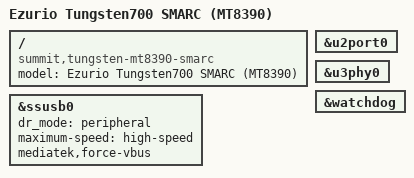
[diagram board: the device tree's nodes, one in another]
// SPDX-License-Identifier: (GPL-2.0 OR MIT)
/*
 * Copyright (C) 2026 Ezurio LLC
 */

/dts-v1/;

#include "tungsten-mt8390-smarc.dtsi"

/ {
	model = "Ezurio Tungsten700 SMARC (MT8390)";
	compatible = "summit,tungsten-mt8390-smarc",
	             "mediatek,mt8390", "mediatek,mt8188";
};

&ssusb0 {
	dr_mode = "peripheral";
	maximum-speed = "high-speed";
	/* VBUS-valid is not sensed by the SoC in device role; BROM forces it, so do the same */
	mediatek,force-vbus;

	status = "okay";
};

&u2port0 {
	status = "okay";
};

&u3phy0 {
	status = "okay";
};

&watchdog {
	status = "okay";
};
